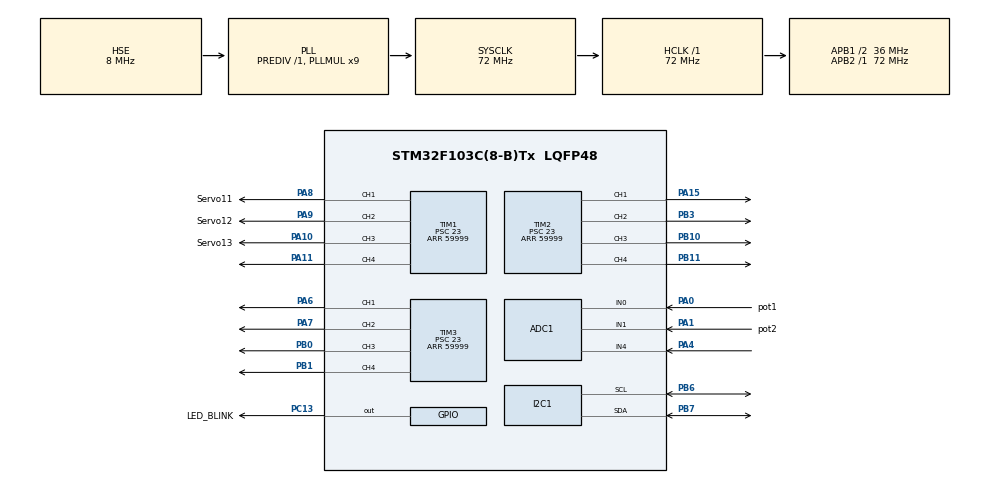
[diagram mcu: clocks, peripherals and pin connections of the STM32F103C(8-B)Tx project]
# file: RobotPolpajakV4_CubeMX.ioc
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ADC1.Channel-52\#ChannelRegularConversion=ADC_CHANNEL_0
ADC1.Channel-53\#ChannelRegularConversion=ADC_CHANNEL_1
ADC1.Channel-54\#ChannelRegularConversion=ADC_CHANNEL_4
ADC1.ContinuousConvMode=ENABLE
ADC1.DataAlign=ADC_DATAALIGN_RIGHT
ADC1.DiscontinuousConvMode=DISABLE
ADC1.EnableAnalogWatchDog=false
ADC1.EnableRegularConversion=ENABLE
ADC1.ExternalTrigConv=ADC_SOFTWARE_START
ADC1.InjNumberOfConversion=0
ADC1.NbrOfConversion=3
ADC1.NbrOfConversionFlag=1
ADC1.Rank-52\#ChannelRegularConversion=1
ADC1.Rank-53\#ChannelRegularConversion=2
ADC1.Rank-54\#ChannelRegularConversion=3
ADC1.SamplingTime-52\#ChannelRegularConversion=ADC_SAMPLETIME_239CYCLES_5
ADC1.SamplingTime-53\#ChannelRegularConversion=ADC_SAMPLETIME_239CYCLES_5
ADC1.SamplingTime-54\#ChannelRegularConversion=ADC_SAMPLETIME_239CYCLES_5
ADC1.ScanConvMode=ADC_SCAN_ENABLE
ADC1.master=1
Dma.ADC1.0.Direction=DMA_PERIPH_TO_MEMORY
Dma.ADC1.0.Instance=DMA1_Channel1
Dma.ADC1.0.MemDataAlignment=DMA_MDATAALIGN_HALFWORD
Dma.ADC1.0.MemInc=DMA_MINC_ENABLE
Dma.ADC1.0.Mode=DMA_CIRCULAR
Dma.ADC1.0.PeriphDataAlignment=DMA_PDATAALIGN_HALFWORD
Dma.ADC1.0.PeriphInc=DMA_PINC_DISABLE
Dma.ADC1.0.Priority=DMA_PRIORITY_LOW
Dma.Request0=ADC1
Mcu.Family=STM32F1
Mcu.Name=STM32F103C(8-B)Tx
Mcu.Package=LQFP48
NVIC.DMA1_Channel1_IRQn=true\:0\:0\:false\:false\:true\:false
NVIC.PriorityGroup=NVIC_PRIORITYGROUP_4
PA0-WKUP.GPIO_Label=pot1
PA0-WKUP.Signal=ADCx_IN0
PA1.GPIO_Label=pot2
PA1.Signal=ADCx_IN1
PA10.GPIO_Label=Servo13
PA10.GPIO_ModeDefaultPP=GPIO_MODE_AF_PP
PA10.GPIO_Speed=GPIO_SPEED_FREQ_HIGH
PA10.Signal=S_TIM1_CH3
PA11.GPIO_Speed=GPIO_SPEED_FREQ_HIGH
PA11.Signal=S_TIM1_CH4
PA13.Mode=Serial_Wire
PA13.Signal=SYS_JTMS-SWDIO
PA14.Mode=Serial_Wire
PA14.Signal=SYS_JTCK-SWCLK
PA15.GPIO_Speed=GPIO_SPEED_FREQ_HIGH
PA15.Signal=S_TIM2_CH1_ETR
PA4.Signal=ADCx_IN4
PA6.GPIO_Speed=GPIO_SPEED_FREQ_HIGH
PA6.Signal=S_TIM3_CH1
PA7.GPIO_Speed=GPIO_SPEED_FREQ_HIGH
PA7.Signal=S_TIM3_CH2
PA8.GPIO_Label=Servo11
PA8.GPIO_ModeDefaultPP=GPIO_MODE_AF_PP
PA8.GPIO_Speed=GPIO_SPEED_FREQ_HIGH
PA8.Signal=S_TIM1_CH1
PA9.GPIO_Label=Servo12
PA9.GPIO_ModeDefaultPP=GPIO_MODE_AF_PP
PA9.GPIO_Speed=GPIO_SPEED_FREQ_HIGH
PA9.Signal=S_TIM1_CH2
PB0.GPIO_Speed=GPIO_SPEED_FREQ_HIGH
PB0.Signal=S_TIM3_CH3
PB1.GPIO_Speed=GPIO_SPEED_FREQ_HIGH
PB1.Signal=S_TIM3_CH4
PB10.GPIO_Speed=GPIO_SPEED_FREQ_HIGH
PB10.Signal=S_TIM2_CH3
PB11.GPIO_Speed=GPIO_SPEED_FREQ_HIGH
PB11.Signal=S_TIM2_CH4
PB3.GPIO_Speed=GPIO_SPEED_FREQ_HIGH
PB3.Signal=S_TIM2_CH2
PB6.Mode=I2C
PB6.Signal=I2C1_SCL
PB7.Mode=I2C
PB7.Signal=I2C1_SDA
PC13-TAMPER-RTC.GPIO_Label=LED_BLINK
PC13-TAMPER-RTC.Signal=GPIO_Output
PD0-OSC_IN.Mode=HSE-External-Oscillator
PD0-OSC_IN.Signal=RCC_OSC_IN
PD1-OSC_OUT.Mode=HSE-External-Oscillator
PD1-OSC_OUT.Signal=RCC_OSC_OUT
ProjectManager.HeapSize=0x200
ProjectManager.StackSize=0x400
ProjectManager.TargetToolchain=TrueSTUDIO
RCC.ADCPresc=RCC_ADCPCLK2_DIV6
RCC.AHBFreq_Value=72000000
RCC.APB1CLKDivider=RCC_HCLK_DIV2
RCC.APB1Freq_Value=36000000
RCC.APB1TimFreq_Value=72000000
RCC.APB2Freq_Value=72000000
RCC.APB2TimFreq_Value=72000000
RCC.HCLKFreq_Value=72000000
RCC.PLLMUL=RCC_PLL_MUL9
RCC.PLLSourceVirtual=RCC_PLLSOURCE_HSE
RCC.RCC_MCOSource=RCC_MCO1SOURCE_PLLCLK
RCC.SYSCLKFreq_VALUE=72000000
RCC.SYSCLKSource=RCC_SYSCLKSOURCE_PLLCLK
RCC.USBFreq_Value=72000000
SH.ADCx_IN0.0=ADC1_IN0,IN0
SH.ADCx_IN1.0=ADC1_IN1,IN1
SH.ADCx_IN4.0=ADC1_IN4,IN4
SH.S_TIM1_CH1.0=TIM1_CH1,PWM Generation1 CH1
SH.S_TIM1_CH2.0=TIM1_CH2,PWM Generation2 CH2
SH.S_TIM1_CH3.0=TIM1_CH3,PWM Generation3 CH3
SH.S_TIM1_CH4.0=TIM1_CH4,PWM Generation4 CH4
SH.S_TIM2_CH1_ETR.0=TIM2_CH1,PWM Generation1 CH1
SH.S_TIM2_CH2.0=TIM2_CH2,PWM Generation2 CH2
SH.S_TIM2_CH3.0=TIM2_CH3,PWM Generation3 CH3
SH.S_TIM2_CH4.0=TIM2_CH4,PWM Generation4 CH4
SH.S_TIM3_CH1.0=TIM3_CH1,PWM Generation1 CH1
SH.S_TIM3_CH2.0=TIM3_CH2,PWM Generation2 CH2
SH.S_TIM3_CH3.0=TIM3_CH3,PWM Generation3 CH3
SH.S_TIM3_CH4.0=TIM3_CH4,PWM Generation4 CH4
TIM1.Channel-PWM\ Generation1\ CH1=TIM_CHANNEL_1
TIM1.Channel-PWM\ Generation2\ CH2=TIM_CHANNEL_2
TIM1.Channel-PWM\ Generation3\ CH3=TIM_CHANNEL_3
TIM1.Channel-PWM\ Generation4\ CH4=TIM_CHANNEL_4
TIM1.Period=59999
TIM1.Prescaler=23
TIM2.Channel-PWM\ Generation1\ CH1=TIM_CHANNEL_1
TIM2.Channel-PWM\ Generation2\ CH2=TIM_CHANNEL_2
TIM2.Channel-PWM\ Generation3\ CH3=TIM_CHANNEL_3
TIM2.Channel-PWM\ Generation4\ CH4=TIM_CHANNEL_4
TIM2.Period=59999
TIM2.Prescaler=23
TIM3.Channel-PWM\ Generation1\ CH1=TIM_CHANNEL_1
TIM3.Channel-PWM\ Generation2\ CH2=TIM_CHANNEL_2
TIM3.Channel-PWM\ Generation3\ CH3=TIM_CHANNEL_3
TIM3.Channel-PWM\ Generation4\ CH4=TIM_CHANNEL_4
TIM3.Period=59999
TIM3.Prescaler=23
VP_TIM1_VS_ClockSourceINT.Mode=Internal
VP_TIM2_VS_ClockSourceINT.Mode=Internal
VP_TIM3_VS_ClockSourceINT.Mode=Internal
board=RobotPolpajakV4_CubeMX

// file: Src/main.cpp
/**
  ******************************************************************************
  * @file           : main.c
  * @brief          : Main program body
  ******************************************************************************
  ** This notice applies to any and all portions of this file
  * that are not between comment pairs USER CODE BEGIN and
  * USER CODE END. Other portions of this file, whether
  * inserted by the user or by software development tools
  * are owned by their respective copyright owners.
  *
  * COPYRIGHT(c) 2018 STMicroelectronics
  *
  * Redistribution and use in source and binary forms, with or without modification,
  * are permitted provided that the following conditions are met:
  *   1. Redistributions of source code must retain the above copyright notice,
  *      this list of conditions and the following disclaimer.
  *   2. Redistributions in binary form must reproduce the above copyright notice,
  *      this list of conditions and the following disclaimer in the documentation
  *      and/or other materials provided with the distribution.
  *   3. Neither the name of STMicroelectronics nor the names of its contributors
  *      may be used to endorse or promote products derived from this software
  *      without specific prior written permission.
  *
  * THIS SOFTWARE IS PROVIDED BY THE COPYRIGHT HOLDERS AND CONTRIBUTORS "AS IS"
  * AND ANY EXPRESS OR IMPLIED WARRANTIES, INCLUDING, BUT NOT LIMITED TO, THE
  * IMPLIED WARRANTIES OF MERCHANTABILITY AND FITNESS FOR A PARTICULAR PURPOSE ARE
  * DISCLAIMED. IN NO EVENT SHALL THE COPYRIGHT HOLDER OR CONTRIBUTORS BE LIABLE
  * FOR ANY DIRECT, INDIRECT, INCIDENTAL, SPECIAL, EXEMPLARY, OR CONSEQUENTIAL
  * DAMAGES (INCLUDING, BUT NOT LIMITED TO, PROCUREMENT OF SUBSTITUTE GOODS OR
  * SERVICES; LOSS OF USE, DATA, OR PROFITS; OR BUSINESS INTERRUPTION) HOWEVER
  * CAUSED AND ON ANY THEORY OF LIABILITY, WHETHER IN CONTRACT, STRICT LIABILITY,
  * OR TORT (INCLUDING NEGLIGENCE OR OTHERWISE) ARISING IN ANY WAY OUT OF THE USE
  * OF THIS SOFTWARE, EVEN IF ADVISED OF THE POSSIBILITY OF SUCH DAMAGE.
  *
  ******************************************************************************
  */
#include "main.h"
#include "stm32f1xx_hal.h"
#include "adc.h"
#include "dma.h"
#include "i2c.h"
#include "tim.h"
#include "gpio.h"

/* USER CODE BEGIN Includes */
#include "MainLoop.hpp"

/* USER CODE END Includes */

/* USER CODE BEGIN PV */
/* Private variables ---------------------------------------------------------*/

/* USER CODE END PV */

void SystemClock_Config(void);

/* USER CODE BEGIN PFP */
/* Private function prototypes -----------------------------------------------*/

/* USER CODE END PFP */

int main(void)
{

  /* MCU Configuration----------------------------------------------------------*/

  /* Reset of all peripherals, Initializes the Flash interface and the Systick. */
  HAL_Init();

  /* Configure the system clock */
  SystemClock_Config();

  /* Initialize all configured peripherals */
  MX_GPIO_Init();
  MX_DMA_Init();
  MX_TIM1_Init();
  MX_ADC1_Init();
  MX_TIM2_Init();
  MX_TIM3_Init();
  MX_I2C1_Init();

  /* Infinite loop */
  /* USER CODE BEGIN WHILE */
	while (1)
	{
		//##############################################################
		//############ START MAIN LOOP #################################
		MainLoop();
		//############ END MAIN LOOP   #################################
		//##############################################################

  /* USER CODE END WHILE */

	}

}

void SystemClock_Config(void)
{

  RCC_OscInitTypeDef RCC_OscInitStruct;
  RCC_ClkInitTypeDef RCC_ClkInitStruct;
  RCC_PeriphCLKInitTypeDef PeriphClkInit;

    /**Initializes the CPU, AHB and APB busses clocks
    */
  RCC_OscInitStruct.OscillatorType = RCC_OSCILLATORTYPE_HSE;
  RCC_OscInitStruct.HSEState = RCC_HSE_ON;
  RCC_OscInitStruct.HSEPredivValue = RCC_HSE_PREDIV_DIV1;
  RCC_OscInitStruct.HSIState = RCC_HSI_ON;
  RCC_OscInitStruct.PLL.PLLState = RCC_PLL_ON;
  RCC_OscInitStruct.PLL.PLLSource = RCC_PLLSOURCE_HSE;
  RCC_OscInitStruct.PLL.PLLMUL = RCC_PLL_MUL9;
  if (HAL_RCC_OscConfig(&RCC_OscInitStruct) != HAL_OK)
  {
    _Error_Handler(__FILE__, __LINE__);
  }

    /**Initializes the CPU, AHB and APB busses clocks
    */
  RCC_ClkInitStruct.ClockType = RCC_CLOCKTYPE_HCLK|RCC_CLOCKTYPE_SYSCLK
                              |RCC_CLOCKTYPE_PCLK1|RCC_CLOCKTYPE_PCLK2;
  RCC_ClkInitStruct.SYSCLKSource = RCC_SYSCLKSOURCE_PLLCLK;
  RCC_ClkInitStruct.AHBCLKDivider = RCC_SYSCLK_DIV1;
  RCC_ClkInitStruct.APB1CLKDivider = RCC_HCLK_DIV2;
  RCC_ClkInitStruct.APB2CLKDivider = RCC_HCLK_DIV1;

  if (HAL_RCC_ClockConfig(&RCC_ClkInitStruct, FLASH_LATENCY_2) != HAL_OK)
  {
    _Error_Handler(__FILE__, __LINE__);
  }

  PeriphClkInit.PeriphClockSelection = RCC_PERIPHCLK_ADC;
  PeriphClkInit.AdcClockSelection = RCC_ADCPCLK2_DIV6;
  if (HAL_RCCEx_PeriphCLKConfig(&PeriphClkInit) != HAL_OK)
  {
    _Error_Handler(__FILE__, __LINE__);
  }

    /**Configure the Systick interrupt time
    */
  HAL_SYSTICK_Config(HAL_RCC_GetHCLKFreq()/1000);

    /**Configure the Systick
    */
  HAL_SYSTICK_CLKSourceConfig(SYSTICK_CLKSOURCE_HCLK);

  /* SysTick_IRQn interrupt configuration */
  HAL_NVIC_SetPriority(SysTick_IRQn, 0, 0);
}

void _Error_Handler(char *file, int line)
{
	while (1) {
	}
}

/************************ (C) COPYRIGHT STMicroelectronics *****END OF FILE****/
